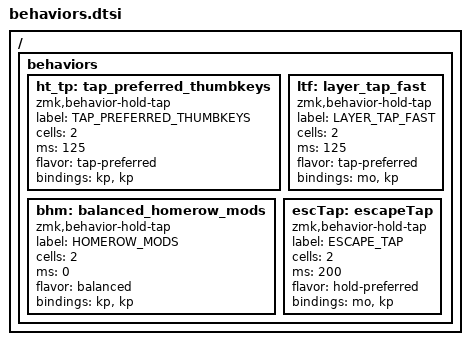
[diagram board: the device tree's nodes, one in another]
/*
 * Base behaviors for ZMK keymaps
 *
 * This file defines common behaviors used across different keyboards.
 */

#include <dt-bindings/zmk/keys.h>

/ {
  behaviors {
  // Tap preferred hold-tap for thumb keys
  ht_tp:
    tap_preferred_thumbkeys {
      compatible = "zmk,behavior-hold-tap";
      label = "TAP_PREFERRED_THUMBKEYS";
#binding - cells = < 2>;
      tapping - term - ms = <200>;
      quick - tap - ms = <200>;
      require - prior - idle - ms = <125>;
      flavor = "tap-preferred";
      bindings = <&kp>, <&kp>;
    };

  // Balanced hold-tap for homerow mods
  // Flavor balanced provides a good compromise between hold and tap preferences
  bhm:
    balanced_homerow_mods {
      compatible = "zmk,behavior-hold-tap";
      label = "HOMEROW_MODS";
#binding - cells = < 2>;
      tapping - term - ms = <200>;
      quick - tap - ms = <0>;
      flavor = "balanced";
      bindings = <&kp>, <&kp>;
    };

  // Fast layer tap behavior
  ltf:
    layer_tap_fast {
      compatible = "zmk,behavior-hold-tap";
      label = "LAYER_TAP_FAST";
#binding - cells = < 2>;
      tapping - term - ms = <200>;
      quick - tap - ms = <200>;
      require - prior - idle - ms = <125>;
      flavor = "tap-preferred";
      bindings = <&mo>, <&kp>;
    };

  // Escape tap behavior
  escTap:
    escapeTap {
      compatible = "zmk,behavior-hold-tap";
      label = "ESCAPE_TAP";
#binding - cells = < 2>;
      tapping - term - ms = <200>;
      flavor = "hold-preferred";
      bindings = <&mo>, <&kp>;
    };
  };
};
